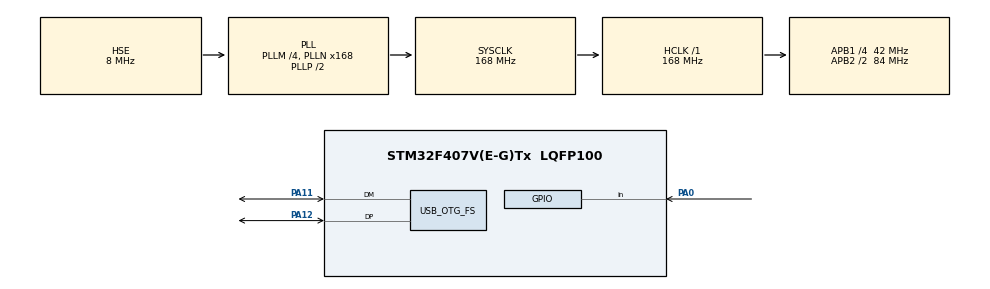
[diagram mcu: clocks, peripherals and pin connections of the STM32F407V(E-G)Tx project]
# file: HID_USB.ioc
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Mcu.Family=STM32F4
Mcu.Name=STM32F407V(E-G)Tx
Mcu.Package=LQFP100
NVIC.OTG_FS_IRQn=true\:0\:0\:false\:false\:true\:false
NVIC.PriorityGroup=NVIC_PRIORITYGROUP_0
PA0-WKUP.Signal=GPIO_Input
PA11.Mode=Device_Only
PA11.Signal=USB_OTG_FS_DM
PA12.Mode=Device_Only
PA12.Signal=USB_OTG_FS_DP
PA13.Mode=Serial_Wire
PA13.Signal=SYS_JTMS-SWDIO
PA14.Mode=Serial_Wire
PA14.Signal=SYS_JTCK-SWCLK
PH0-OSC_IN.Mode=HSE-External-Oscillator
PH0-OSC_IN.Signal=RCC_OSC_IN
PH1-OSC_OUT.Mode=HSE-External-Oscillator
PH1-OSC_OUT.Signal=RCC_OSC_OUT
ProjectManager.HeapSize=0x200
ProjectManager.StackSize=0x400
ProjectManager.TargetToolchain=MDK-ARM V5
RCC.48MHZClocksFreq_Value=48000000
RCC.AHBFreq_Value=168000000
RCC.APB1CLKDivider=RCC_HCLK_DIV4
RCC.APB1Freq_Value=42000000
RCC.APB1TimFreq_Value=84000000
RCC.APB2CLKDivider=RCC_HCLK_DIV2
RCC.APB2Freq_Value=84000000
RCC.APB2TimFreq_Value=168000000
RCC.CortexFreq_Value=168000000
RCC.HCLKFreq_Value=168000000
RCC.HSE_VALUE=8000000
RCC.HSI_VALUE=16000000
RCC.LSE_VALUE=32768
RCC.PLLM=4
RCC.PLLN=168
RCC.PLLQ=7
RCC.SYSCLKFreq_VALUE=168000000
RCC.SYSCLKSource=RCC_SYSCLKSOURCE_PLLCLK
RCC.VCOOutputFreq_Value=336000000
TIM6.Period=1000
TIM6.Prescaler=41999
TIM6.TIM_MasterOutputTrigger=TIM_TRGO_UPDATE
USB_DEVICE.CLASS_NAME_FS=CUSTOMHID
USB_DEVICE.VirtualMode-CUSTOM_HID_FS=CustomHid
USB_DEVICE.VirtualModeFS=Custom_Hid_FS
USB_OTG_FS.VirtualMode=Device_Only
VP_TIM6_VS_ClockSourceINT.Mode=Enable_Timer
VP_USB_DEVICE_VS_USB_DEVICE_CUSTOM_HID_FS.Mode=CUSTOM_HID_FS
board=STM32F4DISCOVERY

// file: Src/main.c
/**
  ******************************************************************************
  * @file           : main.c
  * @brief          : Main program body
  ******************************************************************************
  * This notice applies to any and all portions of this file
  * that are not between comment pairs USER CODE BEGIN and
  * USER CODE END. Other portions of this file, whether
  * inserted by the user or by software development tools
  * are owned by their respective copyright owners.
  *
  * Copyright (c) 2018 STMicroelectronics International N.V.
  * All rights reserved.
  *
  * Redistribution and use in source and binary forms, with or without
  * modification, are permitted, provided that the following conditions are met:
  *
  * 1. Redistribution of source code must retain the above copyright notice,
  *    this list of conditions and the following disclaimer.
  * 2. Redistributions in binary form must reproduce the above copyright notice,
  *    this list of conditions and the following disclaimer in the documentation
  *    and/or other materials provided with the distribution.
  * 3. Neither the name of STMicroelectronics nor the names of other
  *    contributors to this software may be used to endorse or promote products
  *    derived from this software without specific written permission.
  * 4. This software, including modifications and/or derivative works of this
  *    software, must execute solely and exclusively on microcontroller or
  *    microprocessor devices manufactured by or for STMicroelectronics.
  * 5. Redistribution and use of this software other than as permitted under
  *    this license is void and will automatically terminate your rights under
  *    this license.
  *
  * THIS SOFTWARE IS PROVIDED BY STMICROELECTRONICS AND CONTRIBUTORS "AS IS"
  * AND ANY EXPRESS, IMPLIED OR STATUTORY WARRANTIES, INCLUDING, BUT NOT
  * LIMITED TO, THE IMPLIED WARRANTIES OF MERCHANTABILITY, FITNESS FOR A
  * PARTICULAR PURPOSE AND NON-INFRINGEMENT OF THIRD PARTY INTELLECTUAL PROPERTY
  * RIGHTS ARE DISCLAIMED TO THE FULLEST EXTENT PERMITTED BY LAW. IN NO EVENT
  * SHALL STMICROELECTRONICS OR CONTRIBUTORS BE LIABLE FOR ANY DIRECT, INDIRECT,
  * INCIDENTAL, SPECIAL, EXEMPLARY, OR CONSEQUENTIAL DAMAGES (INCLUDING, BUT NOT
  * LIMITED TO, PROCUREMENT OF SUBSTITUTE GOODS OR SERVICES; LOSS OF USE, DATA,
  * OR PROFITS; OR BUSINESS INTERRUPTION) HOWEVER CAUSED AND ON ANY THEORY OF
  * LIABILITY, WHETHER IN CONTRACT, STRICT LIABILITY, OR TORT (INCLUDING
  * NEGLIGENCE OR OTHERWISE) ARISING IN ANY WAY OUT OF THE USE OF THIS SOFTWARE,
  * EVEN IF ADVISED OF THE POSSIBILITY OF SUCH DAMAGE.
  *
  ******************************************************************************
  */
#include "main.h"
#include "stm32f4xx_hal.h"
#include "usb_device.h"
#include "usbd_customhid.h"

/* USER CODE BEGIN Includes */
#define CURSOR_STEP     1

/* USER CODE END Includes */

TIM_HandleTypeDef htim6;

/* USER CODE BEGIN PV */
/* Private variables ---------------------------------------------------------*/
extern USBD_HandleTypeDef  hUsbDeviceFS;

uint8_t dataToSend[5];

uint8_t btn_stat=0;
/* USER CODE END PV */

void SystemClock_Config(void);
static void MX_GPIO_Init(void);
static void MX_TIM6_Init(void);

/* USER CODE BEGIN PFP */
/* Private function prototypes -----------------------------------------------*/

/* USER CODE END PFP */

/* USER CODE BEGIN 0 */
//static void GetPointerData(uint8_t *pbuf)
//{
//  static uint8_t cnt = 0; //счетчик циклов
//  static uint8_t drct = 0; //направление курсора
//  int8_t  x = 0, y = 0 , but = 0;
//
//        if((cnt<20)&&(drct==0))
//        {
//                drct=0;
//    x = CURSOR_STEP;
//    y = CURSOR_STEP;
//                cnt++;
//  }
//  else if (cnt>0)
//  {
//                drct=1;
//    x = -CURSOR_STEP;
//    y = -CURSOR_STEP;
//                cnt--;
//  }
//        else drct=0;
//        pbuf[0] = but;
//        pbuf[1] = x;
//        pbuf[2] = y;
//        pbuf[3] = 0;
//}
//static void GetPointerDataButton(uint8_t *pbuf)
//{
//	int8_t  x = 0, y = 0 , but = 0;
//	 if(HAL_GPIO_ReadPin(GPIOA,GPIO_PIN_0)==GPIO_PIN_SET) but=2;
//        else but=0;
//        pbuf[0] = but;
//        pbuf[1] = x;
//        pbuf[2] = y;
//        pbuf[3] = 0;
//}

/* USER CODE END 0 */

int main(void)
{

  /* MCU Configuration----------------------------------------------------------*/

  /* Reset of all peripherals, Initializes the Flash interface and the Systick. */
  HAL_Init();

  /* Configure the system clock */
  SystemClock_Config();

  /* Initialize all configured peripherals */
  MX_GPIO_Init();
  MX_USB_DEVICE_Init();
  MX_TIM6_Init();
  /* USER CODE BEGIN 2 */
	 HAL_TIM_Base_Start_IT(&htim6);
  /* USER CODE END 2 */

  /* Infinite loop */
  while (1)
  {

  /* USER CODE BEGIN 3 */
	 HAL_Delay(100);
   //GetPointerData(HID_Buffer);

  }
  /* USER CODE END 3 */

}

void SystemClock_Config(void)
{

  RCC_OscInitTypeDef RCC_OscInitStruct;
  RCC_ClkInitTypeDef RCC_ClkInitStruct;

    /**Configure the main internal regulator output voltage
    */
  __HAL_RCC_PWR_CLK_ENABLE();

  __HAL_PWR_VOLTAGESCALING_CONFIG(PWR_REGULATOR_VOLTAGE_SCALE1);

    /**Initializes the CPU, AHB and APB busses clocks
    */
  RCC_OscInitStruct.OscillatorType = RCC_OSCILLATORTYPE_HSE;
  RCC_OscInitStruct.HSEState = RCC_HSE_ON;
  RCC_OscInitStruct.PLL.PLLState = RCC_PLL_ON;
  RCC_OscInitStruct.PLL.PLLSource = RCC_PLLSOURCE_HSE;
  RCC_OscInitStruct.PLL.PLLM = 4;
  RCC_OscInitStruct.PLL.PLLN = 168;
  RCC_OscInitStruct.PLL.PLLP = RCC_PLLP_DIV2;
  RCC_OscInitStruct.PLL.PLLQ = 7;
  if (HAL_RCC_OscConfig(&RCC_OscInitStruct) != HAL_OK)
  {
    _Error_Handler(__FILE__, __LINE__);
  }

    /**Initializes the CPU, AHB and APB busses clocks
    */
  RCC_ClkInitStruct.ClockType = RCC_CLOCKTYPE_HCLK|RCC_CLOCKTYPE_SYSCLK
                              |RCC_CLOCKTYPE_PCLK1|RCC_CLOCKTYPE_PCLK2;
  RCC_ClkInitStruct.SYSCLKSource = RCC_SYSCLKSOURCE_PLLCLK;
  RCC_ClkInitStruct.AHBCLKDivider = RCC_SYSCLK_DIV1;
  RCC_ClkInitStruct.APB1CLKDivider = RCC_HCLK_DIV4;
  RCC_ClkInitStruct.APB2CLKDivider = RCC_HCLK_DIV2;

  if (HAL_RCC_ClockConfig(&RCC_ClkInitStruct, FLASH_LATENCY_5) != HAL_OK)
  {
    _Error_Handler(__FILE__, __LINE__);
  }

    /**Configure the Systick interrupt time
    */
  HAL_SYSTICK_Config(HAL_RCC_GetHCLKFreq()/1000);

    /**Configure the Systick
    */
  HAL_SYSTICK_CLKSourceConfig(SYSTICK_CLKSOURCE_HCLK);

  /* SysTick_IRQn interrupt configuration */
  HAL_NVIC_SetPriority(SysTick_IRQn, 0, 0);
}

/* TIM6 init function */
static void MX_TIM6_Init(void)
{

  TIM_MasterConfigTypeDef sMasterConfig;

  htim6.Instance = TIM6;
  htim6.Init.Prescaler = 41999;
  htim6.Init.CounterMode = TIM_COUNTERMODE_UP;
  htim6.Init.Period = 1000;
  if (HAL_TIM_Base_Init(&htim6) != HAL_OK)
  {
    _Error_Handler(__FILE__, __LINE__);
  }

  sMasterConfig.MasterOutputTrigger = TIM_TRGO_UPDATE;
  sMasterConfig.MasterSlaveMode = TIM_MASTERSLAVEMODE_DISABLE;
  if (HAL_TIMEx_MasterConfigSynchronization(&htim6, &sMasterConfig) != HAL_OK)
  {
    _Error_Handler(__FILE__, __LINE__);
  }

}

/** Configure pins as
        * Analog
        * Input
        * Output
        * EVENT_OUT
        * EXTI
*/
static void MX_GPIO_Init(void)
{

  GPIO_InitTypeDef GPIO_InitStruct;

  /* GPIO Ports Clock Enable */
  __HAL_RCC_GPIOH_CLK_ENABLE();
  __HAL_RCC_GPIOA_CLK_ENABLE();

  /*Configure GPIO pin : PA0 */
  GPIO_InitStruct.Pin = GPIO_PIN_0;
  GPIO_InitStruct.Mode = GPIO_MODE_INPUT;
  GPIO_InitStruct.Pull = GPIO_NOPULL;
  HAL_GPIO_Init(GPIOA, &GPIO_InitStruct);

}

/* USER CODE BEGIN 4 */
void HAL_TIM_PeriodElapsedCallback (TIM_HandleTypeDef *htim6)
{
        if(btn_stat==0)        {dataToSend[0] = 6;dataToSend[1] = 1;}
        else if(btn_stat==1)        {dataToSend[0] = 6;dataToSend[1] = 0;}
        else if(btn_stat==2)        {dataToSend[0] = 5;dataToSend[1] = 1;}
        else if(btn_stat==3)        {dataToSend[0] = 5;dataToSend[1] = 0;}
        dataToSend[2] = 'H';
  dataToSend[3] = 'I';
        dataToSend[4] = 'D';
  USBD_CUSTOM_HID_SendReport(&hUsbDeviceFS, dataToSend, 5);
        btn_stat++;
        if(btn_stat>3) btn_stat=0;
}
/* USER CODE END 4 */

void _Error_Handler(char *file, int line)
{
  while(1)
  {
  }
}

/************************ (C) COPYRIGHT STMicroelectronics *****END OF FILE****/
